AUTOSAR XML (schema 00048)
package /HuaweiMDC/FunctionalSoftware/LidarDetectionApplication/Execution
  executable LidarDetectionExecutable
    root sw component prototype LidarDetectionRootSwComponent: application-type=LidarDetectionApplicationSwComponent
package /HuaweiMDC/FunctionalSoftware/LidarDetectionApplication/SwComponent
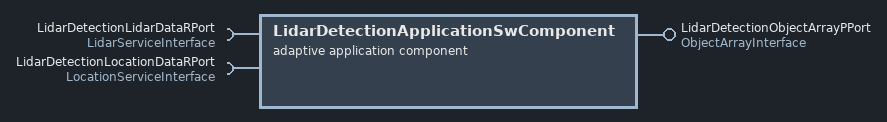
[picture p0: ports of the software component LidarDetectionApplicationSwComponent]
  adaptive application sw component type LidarDetectionApplicationSwComponent
    require port LidarDetectionLidarDataRPort: required-interface=LidarServiceInterface
    require port LidarDetectionLocationDataRPort: required-interface=LocationServiceInterface
    provide port LidarDetectionObjectArrayPPort: provided-interface=ObjectArrayInterface
